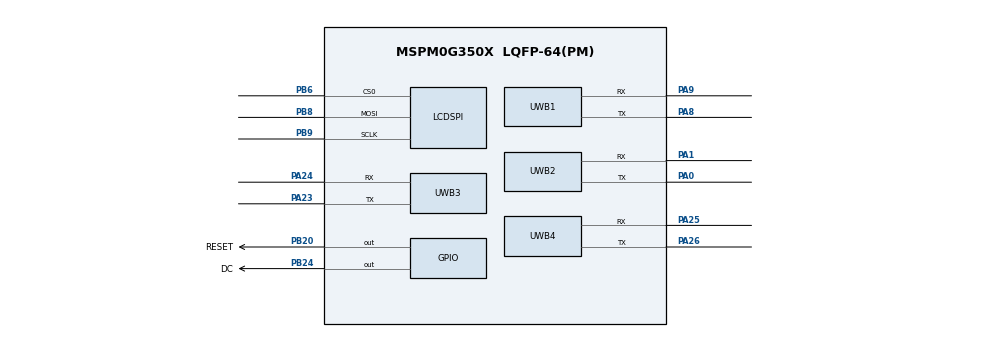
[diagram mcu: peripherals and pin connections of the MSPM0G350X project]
/**
 * Four-UART UWB capture monitor for Tianmengxing MSPM0G3507.
 * Only UART0..3 and the ST7735 SPI display/control GPIO are enabled.
 *
 * @cliArgs --device "MSPM0G350X" --part "Default" --package "LQFP-64(PM)" --product "mspm0_sdk@2.10.00.04"
 * @versions {"tool":"1.26.2+4477"}
 */

const SYSCTL     = scripting.addModule("/ti/driverlib/SYSCTL");
const UART       = scripting.addModule("/ti/driverlib/UART", {}, false);
const GPIO       = scripting.addModule("/ti/driverlib/GPIO", {}, false);
const SPI        = scripting.addModule("/ti/driverlib/SPI", {}, false);
const Board      = scripting.addModule("/ti/driverlib/Board", {}, false);
const UWB1       = UART.addInstance();
const UWB2       = UART.addInstance();
const UWB3       = UART.addInstance();
const UWB4       = UART.addInstance();
const LCDSPI     = SPI.addInstance();
const LCDControl = GPIO.addInstance();

const divider9       = system.clockTree["UDIV"];
divider9.divideValue = 2;

const gate7  = system.clockTree["MFCLKGATE"];
gate7.enable = true;

const multiplier2         = system.clockTree["PLL_QDIV"];
multiplier2.multiplyValue = 4;

const mux4       = system.clockTree["EXHFMUX"];
mux4.inputSelect = "EXHFMUX_XTAL";

const mux8       = system.clockTree["HSCLKMUX"];
mux8.inputSelect = "HSCLKMUX_SYSPLL0";

const mux12       = system.clockTree["SYSPLLMUX"];
mux12.inputSelect = "zSYSPLLMUX_HFCLK";

const pinFunction4        = system.clockTree["HFXT"];
pinFunction4.inputFreq    = 40;
pinFunction4.enable       = true;
pinFunction4.HFXTStartup  = 10;
pinFunction4.HFCLKMonitor = true;

SYSCTL.forceDefaultClkConfig = true;
SYSCTL.clockTreeEn           = true;

UWB1.$name                            = "UWB1";
UWB1.targetBaudRate                   = 115200;
UWB1.enableFIFO                       = true;
UWB1.rxFifoThreshold                  = "DL_UART_RX_FIFO_LEVEL_ONE_ENTRY";
UWB1.enabledInterrupts                = ["RX"];
UWB1.peripheral.$assign               = "UART1";
UWB1.peripheral.rxPin.$assign         = "PA9";
UWB1.peripheral.txPin.$assign         = "PA8";

UWB2.$name                            = "UWB2";
UWB2.targetBaudRate                   = 115200;
UWB2.enableFIFO                       = true;
UWB2.rxFifoThreshold                  = "DL_UART_RX_FIFO_LEVEL_ONE_ENTRY";
UWB2.enabledInterrupts                = ["RX"];
UWB2.peripheral.$assign               = "UART0";
UWB2.peripheral.rxPin.$assign         = "PA1";
UWB2.peripheral.txPin.$assign         = "PA0";

UWB3.$name                            = "UWB3";
UWB3.targetBaudRate                   = 115200;
UWB3.enableFIFO                       = true;
UWB3.rxFifoThreshold                  = "DL_UART_RX_FIFO_LEVEL_ONE_ENTRY";
UWB3.enabledInterrupts                = ["RX"];
UWB3.peripheral.$assign               = "UART2";
UWB3.peripheral.rxPin.$assign         = "PA24";
UWB3.peripheral.txPin.$assign         = "PA23";

UWB4.$name                            = "UWB4";
UWB4.targetBaudRate                   = 115200;
UWB4.enableFIFO                       = true;
UWB4.rxFifoThreshold                  = "DL_UART_RX_FIFO_LEVEL_ONE_ENTRY";
UWB4.enabledInterrupts                = ["RX"];
UWB4.peripheral.$assign               = "UART3";
UWB4.peripheral.rxPin.$assign         = "PA25";
UWB4.peripheral.txPin.$assign         = "PA26";

LCDSPI.$name                         = "LCD_SPI";
LCDSPI.mode                          = "CONTROLLER";
LCDSPI.spiClkSrc                     = "BUSCLK";
LCDSPI.targetBitRate                 = 8000000;
LCDSPI.frameFormat                   = "MOTO4";
LCDSPI.polarity                      = "0";
LCDSPI.phase                         = "0";
LCDSPI.dataSize                      = 8;
LCDSPI.bitOrder                      = "MSB";
LCDSPI.chipSelect                    = ["0"];
LCDSPI.direction                     = "PICO";
LCDSPI.peripheral.$assign            = "SPI1";
LCDSPI.peripheral.sclkPin.$assign    = "PB9";
LCDSPI.peripheral.mosiPin.$assign    = "PB8";
LCDSPI.peripheral.cs0Pin.$assign     = "PB6";
LCDSPI.cs0PinConfig.enableConfig     = true;
LCDSPI.cs0PinConfig.internalResistor = "PULL_UP";
LCDControl.$name = "LCD_CONTROL";
LCDControl.associatedPins.create(2);
LCDControl.associatedPins[0].$name        = "RESET";
LCDControl.associatedPins[0].direction    = "OUTPUT";
LCDControl.associatedPins[0].initialValue = "SET";
LCDControl.associatedPins[0].pin.$assign  = "PB20";
LCDControl.associatedPins[1].$name        = "DC";
LCDControl.associatedPins[1].direction    = "OUTPUT";
LCDControl.associatedPins[1].initialValue = "SET";
LCDControl.associatedPins[1].pin.$assign  = "PB24";

pinFunction4.peripheral.$suggestSolution           = "SYSCTL";
pinFunction4.peripheral.hfxInPin.$suggestSolution  = "PA5";
pinFunction4.peripheral.hfxOutPin.$suggestSolution = "PA6";
Board.peripheral.$suggestSolution                  = "DEBUGSS";
Board.peripheral.swclkPin.$suggestSolution         = "PA20";
Board.peripheral.swdioPin.$suggestSolution         = "PA19";
